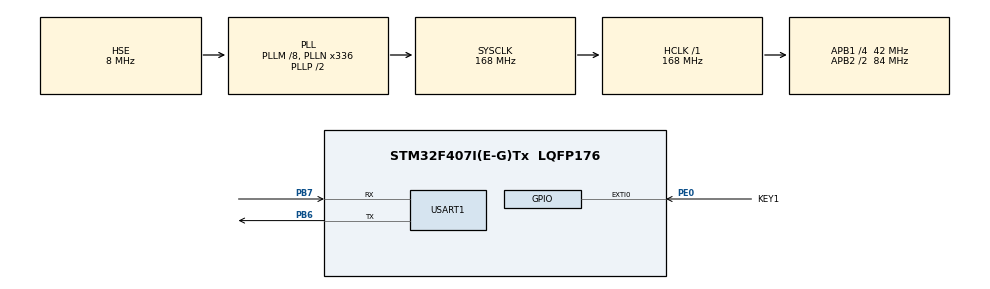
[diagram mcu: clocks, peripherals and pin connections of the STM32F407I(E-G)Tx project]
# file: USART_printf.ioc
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Mcu.Family=STM32F4
PE0.GPIO_PuPd=GPIO_PULLUP
RCC.PLLSourceVirtual=RCC_PLLSOURCE_HSE
PH0-OSC_IN.Signal=RCC_OSC_IN
RCC.CortexFreq_Value=168000000
RCC.APB1CLKDivider=RCC_HCLK_DIV4
RCC.SYSCLKSource=RCC_SYSCLKSOURCE_PLLCLK
ProjectManager.StackSize=0x400
PA13.Signal=SYS_JTMS-SWDIO
ProjectManager.TargetToolchain=MDK-ARM V5.27
RCC.HCLKFreq_Value=168000000
RCC.APB2TimFreq_Value=168000000
PB6.Signal=USART1_TX
PB6.Mode=Asynchronous
RCC.LSE_VALUE=32768
RCC.AHBFreq_Value=168000000
PH0-OSC_IN.Mode=HSE-External-Oscillator
RCC.HSE_VALUE=8000000
board=custom
RCC.VCOOutputFreq_Value=336000000
RCC.APB2Freq_Value=84000000
PA14.Mode=Serial_Wire
PH1-OSC_OUT.Signal=RCC_OSC_OUT
PB7.Signal=USART1_RX
PA13.Mode=Serial_Wire
Mcu.Name=STM32F407I(E-G)Tx
PE0.Signal=GPXTI0
PH1-OSC_OUT.Mode=HSE-External-Oscillator
RCC.48MHZClocksFreq_Value=84000000
NVIC.EXTI0_IRQn=true\:1\:0\:true\:false\:true\:true\:true
RCC.SYSCLKFreq_VALUE=168000000
Mcu.Package=LQFP176
RCC.EnbaleCSS=true
USART1.VirtualMode=VM_ASYNC
PB7.Mode=Asynchronous
PA14.Signal=SYS_JTCK-SWCLK
ProjectManager.HeapSize=0x200
PE0.GPIO_Label=KEY1
RCC.HSI_VALUE=16000000
NVIC.PriorityGroup=NVIC_PRIORITYGROUP_4
RCC.APB2CLKDivider=RCC_HCLK_DIV2
RCC.PLLM=8
RCC.PLLN=336
RCC.APB1TimFreq_Value=84000000
NVIC.USART1_IRQn=true\:0\:0\:false\:false\:true\:true\:true
RCC.APB1Freq_Value=42000000

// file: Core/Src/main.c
/* USER CODE BEGIN Header */
/**
  ******************************************************************************
  * @file           : main.c
  * @brief          : Main program body
  ******************************************************************************
  * @attention
  *
  * <h2><center>&copy; Copyright (c) 2020 STMicroelectronics.
  * All rights reserved.</center></h2>
  *
  * This software component is licensed by ST under BSD 3-Clause license,
  * the "License"; You may not use this file except in compliance with the
  * License. You may obtain a copy of the License at:
  *                        opensource.org/licenses/BSD-3-Clause
  *
  ******************************************************************************
  */
/* USER CODE END Header */
#include "main.h"
#include "usart.h"
#include "gpio.h"

/* USER CODE BEGIN Includes */
#include <stdio.h>
/* USER CODE END Includes */

void SystemClock_Config(void);

int main(void)
{

  /* MCU Configuration--------------------------------------------------------*/

  /* Reset of all peripherals, Initializes the Flash interface and the Systick. */
  HAL_Init();

  /* Configure the system clock */
  SystemClock_Config();

  /* Initialize all configured peripherals */
  MX_GPIO_Init();
  MX_USART1_UART_Init();

  /* Infinite loop */
  while (1)
  {

  }
}

void SystemClock_Config(void)
{
  RCC_OscInitTypeDef RCC_OscInitStruct = {0};
  RCC_ClkInitTypeDef RCC_ClkInitStruct = {0};

  /** Configure the main internal regulator output voltage
  */
  __HAL_RCC_PWR_CLK_ENABLE();
  __HAL_PWR_VOLTAGESCALING_CONFIG(PWR_REGULATOR_VOLTAGE_SCALE1);
  /** Initializes the RCC Oscillators according to the specified parameters
  * in the RCC_OscInitTypeDef structure.
  */
  RCC_OscInitStruct.OscillatorType = RCC_OSCILLATORTYPE_HSE;
  RCC_OscInitStruct.HSEState = RCC_HSE_ON;
  RCC_OscInitStruct.PLL.PLLState = RCC_PLL_ON;
  RCC_OscInitStruct.PLL.PLLSource = RCC_PLLSOURCE_HSE;
  RCC_OscInitStruct.PLL.PLLM = 8;
  RCC_OscInitStruct.PLL.PLLN = 336;
  RCC_OscInitStruct.PLL.PLLP = RCC_PLLP_DIV2;
  RCC_OscInitStruct.PLL.PLLQ = 4;
  if (HAL_RCC_OscConfig(&RCC_OscInitStruct) != HAL_OK)
  {
    Error_Handler();
  }
  /** Initializes the CPU, AHB and APB buses clocks
  */
  RCC_ClkInitStruct.ClockType = RCC_CLOCKTYPE_HCLK|RCC_CLOCKTYPE_SYSCLK
                              |RCC_CLOCKTYPE_PCLK1|RCC_CLOCKTYPE_PCLK2;
  RCC_ClkInitStruct.SYSCLKSource = RCC_SYSCLKSOURCE_PLLCLK;
  RCC_ClkInitStruct.AHBCLKDivider = RCC_SYSCLK_DIV1;
  RCC_ClkInitStruct.APB1CLKDivider = RCC_HCLK_DIV4;
  RCC_ClkInitStruct.APB2CLKDivider = RCC_HCLK_DIV2;

  if (HAL_RCC_ClockConfig(&RCC_ClkInitStruct, FLASH_LATENCY_5) != HAL_OK)
  {
    Error_Handler();
  }
  /** Enables the Clock Security System
  */
  HAL_RCC_EnableCSS();
}

/* USER CODE BEGIN 4 */
void HAL_GPIO_EXTI_Callback(uint16_t GPIO_Pin)
{
  if(HAL_GPIO_ReadPin(GPIOE,GPIO_Pin) == GPIO_PIN_RESET)
	{
		HAL_Delay(10);
		if(HAL_GPIO_ReadPin(GPIOE,GPIO_Pin) == GPIO_PIN_RESET)
		{
			while (HAL_GPIO_ReadPin(GPIOE,GPIO_Pin) != GPIO_PIN_RESET);
			static int cnt = 0;
			printf("Hello World! %d\n", cnt);
			cnt++;
		}
	}
}
/* USER CODE END 4 */

void Error_Handler(void)
{
}

/************************ (C) COPYRIGHT STMicroelectronics *****END OF FILE****/
